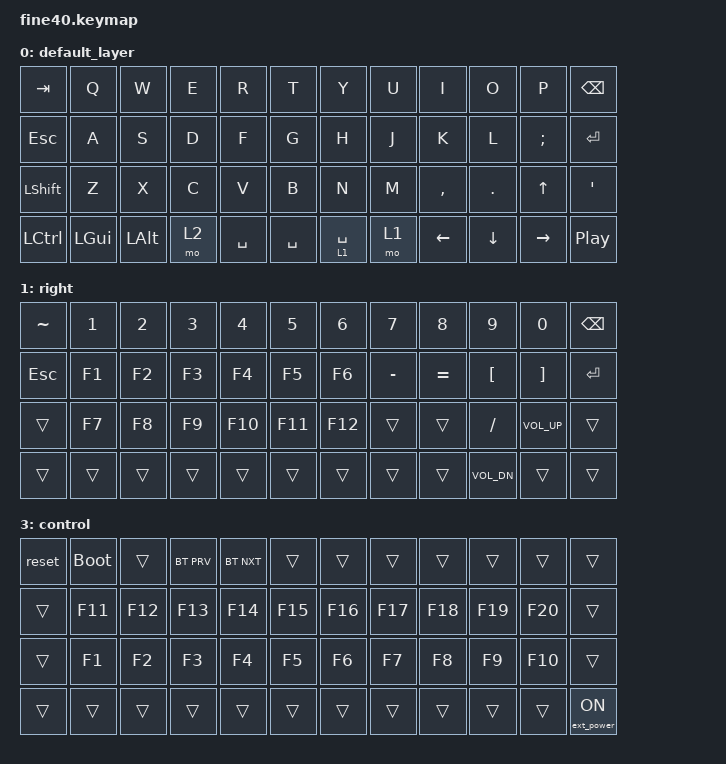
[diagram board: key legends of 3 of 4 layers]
/*
 * Aidan Smith (2021)
 *
 * SPDX-License-Identifier: MIT
 */

#include <behaviors.dtsi>
#include <dt-bindings/zmk/keys.h>
#include <dt-bindings/zmk/bt.h>
#include <dt-bindings/zmk/ext_power.h>

/ {
	keymap {
		compatible = "zmk,keymap";

		default_layer {
			bindings = <
				&kp TAB   &kp Q    &kp W    &kp E    &kp R &kp T     &kp Y &kp U    &kp I     &kp O    &kp P     &kp BSPC
				&kp ESC &kp A    &kp S    &kp D    &kp F &kp G     &kp H &kp J    &kp K     &kp L    &kp SEMI  &kp RET
				&kp LSHFT &kp Z    &kp X    &kp C    &kp V &kp B     &kp N &kp M    &kp COMMA &kp DOT  &kp UP  &kp SQT
				&kp LCTL  &kp LGUI &kp LALT &mo 2 &kp SPACE &kp SPACE &lt 1 SPACE &mo 1 &kp LEFT    &kp DOWN &kp RIGHT &kp C_PP
			>;

			sensor-bindings = <&inc_dec_kp K_VOL_UP K_VOL_DN>;
		};

		right {
			bindings = <
				&kp TILDE &kp N1 &kp N2 &kp N3 &kp N4 &kp N5 &kp N6 &kp N7 &kp N8    &kp N9   &kp N0 &kp BSPC
				&kp ESC       &kp F1 	 &kp F2     &kp F3     &kp F4     &kp F5     &kp F6     &kp MINUS  &kp EQUAL     &kp LBKT     &kp RBKT   &kp RET
				&trans        &kp F7     &kp F8     &kp F9     &kp F10     &kp F11     &kp F12     &trans     &trans &kp FSLH  &kp C_VOL_UP     &trans
				&trans        &trans     &trans     &trans     &trans     &trans     &trans     &trans &trans  &kp C_VOL_DN &trans   &trans
			>;
		};

		left {
			bindings = <
				&kp TILDE &kp LS(N1) &kp LS(N2) &kp LS(N3) &kp LS(N4) &kp LS(N5) &kp LS(N6) &kp LS(N7)    &kp LS(N8)    &kp LS(N9)    &kp LS(N0)   &kp BSPC
				&kp ESC    &kp F1 &kp F2 &kp F3 &kp F4 &kp F5 &kp F6 &kp UNDER &kp PLUS  &kp LBRC  &kp RBRC &kp RET
				&trans    &kp F7 &kp F8 &kp F9 &kp F10 &kp F11 &kp F12 &trans    &trans    &kp QUESTION     &trans   &kp BSLH
				&trans    &trans &trans &trans &trans &trans &trans &trans  &trans &trans &trans
			>;
		};

		control {
			bindings = <
				&reset &bootloader &trans &bt BT_PRV &bt BT_NXT &trans  &trans  &trans  &trans  &trans  &trans  &trans
				&trans &kp F11 	   &kp F12    &kp F13    &kp F14    &kp F15 &kp F16 &kp F17 &kp F18 &kp F19 &kp F20 &trans
				&trans &kp F1      &kp F2     &kp F3     &kp F4     &kp F5  &kp F6  &kp F7  &kp F8  &kp F9  &kp F10 &trans
				&trans &trans      &trans     &trans     &trans     &trans  &trans  &trans  &trans  &trans  &trans  &ext_power EP_ON
			>;
		};
	};
};
